# nrf52 register map
Vendor: Nordic Semiconductor; Series: nrf52; File version: 1
CPU: CM4 r0p1, little endian, MPU, FPU, 3 interrupt priority bits
Registers are 32-bit, read-write, reset 0x0 unless marked. A register's access mark holds for its fields unless they carry their own. Offsets are from the block's base; [hi:lo] are bit positions; 'fields as' and 'values as' point back to an identical list.

## CLOCK — Clock control
Base 0x40000000; alternate view of APPROTECT
0x00 TASKS_HFCLKSTART wo — Start HFCLK crystal oscillator
  [0] TASKS_HFCLKSTART
    1=Trigger task
0x04 TASKS_HFCLKSTOP wo — Stop HFCLK crystal oscillator
  [0] TASKS_HFCLKSTOP
    1=Trigger task
0x08 TASKS_LFCLKSTART wo — Start LFCLK source
  [0] TASKS_LFCLKSTART
    1=Trigger task
0x0C TASKS_LFCLKSTOP wo — Stop LFCLK source
  [0] TASKS_LFCLKSTOP
    1=Trigger task
0x10 TASKS_CAL wo — Start calibration of LFRC oscillator
  [0] TASKS_CAL
    1=Trigger task
0x14 TASKS_CTSTART wo — Start calibration timer
  [0] TASKS_CTSTART
    1=Trigger task
0x18 TASKS_CTSTOP wo — Stop calibration timer
  [0] TASKS_CTSTOP
    1=Trigger task
0x100 EVENTS_HFCLKSTARTED — HFCLK oscillator started
  [0] EVENTS_HFCLKSTARTED
    0=NotGenerated (Event not generated); 1=Generated (Event generated)
0x104 EVENTS_LFCLKSTARTED — LFCLK started
  [0] EVENTS_LFCLKSTARTED
    values as EVENTS_HFCLKSTARTED.EVENTS_HFCLKSTARTED
0x10C EVENTS_DONE — Calibration of LFCLK RC oscillator complete event
  [0] EVENTS_DONE
    values as EVENTS_HFCLKSTARTED.EVENTS_HFCLKSTARTED
0x110 EVENTS_CTTO — Calibration timer timeout
  [0] EVENTS_CTTO
    values as EVENTS_HFCLKSTARTED.EVENTS_HFCLKSTARTED
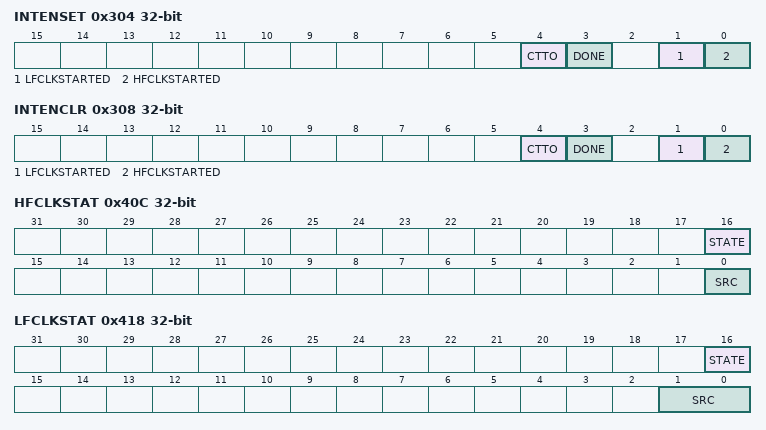
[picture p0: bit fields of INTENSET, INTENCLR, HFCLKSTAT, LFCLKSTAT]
0x304 INTENSET — Enable interrupt
  [all] fields
    on read: 0=Disabled (Read: Disabled); 1=Enabled (Read: Enabled) | on write: 1=Set (Enable)
  [4] CTTO — Write '1' to enable interrupt for event CTTO
  [3] DONE — Write '1' to enable interrupt for event DONE
  [1] LFCLKSTARTED — Write '1' to enable interrupt for event LFCLKSTARTED
  [0] HFCLKSTARTED — Write '1' to enable interrupt for event HFCLKSTARTED
0x308 INTENCLR — Disable interrupt
  [all] fields
    on read: 0=Disabled (Read: Disabled); 1=Enabled (Read: Enabled) | on write: 1=Clear (Disable)
  [4] CTTO — Write '1' to disable interrupt for event CTTO
  [3] DONE — Write '1' to disable interrupt for event DONE
  [1] LFCLKSTARTED — Write '1' to disable interrupt for event LFCLKSTARTED
  [0] HFCLKSTARTED — Write '1' to disable interrupt for event HFCLKSTARTED
0x408 HFCLKRUN ro — Status indicating that HFCLKSTART task has been triggered
  [0] STATUS — HFCLKSTART task triggered or not
    0=NotTriggered (Task not triggered); 1=Triggered (Task triggered)
0x40C HFCLKSTAT ro — HFCLK status
  [16] STATE — HFCLK state
    0=NotRunning (HFCLK not running); 1=Running (HFCLK running)
  [0] SRC — Source of HFCLK
    0=RC (64 MHz internal oscillator (HFINT)); 1=Xtal (64 MHz crystal oscillator (HFXO))
0x414 LFCLKRUN ro — Status indicating that LFCLKSTART task has been triggered
  [0] STATUS — LFCLKSTART task triggered or not
    values as HFCLKRUN.STATUS
0x418 LFCLKSTAT ro — LFCLK status
  [16] STATE — LFCLK state
    0=NotRunning (LFCLK not running); 1=Running (LFCLK running)
  [1:0] SRC — Source of LFCLK
    0=RC (32.768 kHz RC oscillator); 1=Xtal (32.768 kHz crystal oscillator); 2=Synth (32.768 kHz synthesized from HFCLK)
0x41C LFCLKSRCCOPY ro — Copy of LFCLKSRC register, set when LFCLKSTART task was triggered
  [1:0] SRC — Clock source
    values as LFCLKSTAT.SRC
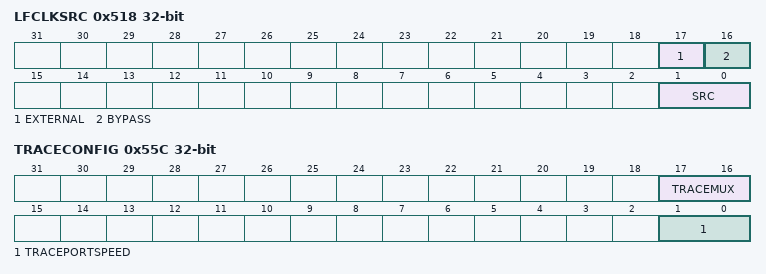
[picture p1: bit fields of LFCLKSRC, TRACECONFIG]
0x518 LFCLKSRC — Clock source for the LFCLK
  [17] EXTERNAL — Enable or disable external source for LFCLK
    0=Disabled (Disable external source (use with Xtal)); 1=Enabled (Enable use of external source instead of Xtal (SRC needs to be set to Xtal))
  [16] BYPASS — Enable or disable bypass of LFCLK crystal oscillator with external clock source
    0=Disabled (Disable (use with Xtal or low-swing external source)); 1=Enabled (Enable (use with rail-to-rail external source))
  [1:0] SRC — Clock source
    values as LFCLKSTAT.SRC
0x538 CTIV — Calibration timer interval
  [6:0] CTIV — Calibration timer interval in multiple of 0.25 seconds. Range: 0.25 seconds to 31.75 seconds.
0x55C TRACECONFIG — Clocking options for the Trace Port debug interface
  [17:16] TRACEMUX — Pin multiplexing of trace signals.
    0=GPIO (GPIOs multiplexed onto all trace-pins); 1=Serial (SWO multiplexed onto P0.18, GPIO multiplexed onto other trace pins); 2=Parallel (TRACECLK and TRACEDATA multiplexed onto P0.20, P0.18, P0.16, P0.15 and P0.14.)
  [1:0] TRACEPORTSPEED — Speed of Trace Port clock. Note that the TRACECLK pin will output this clock divided by two.
    0=32 MHz Trace Port clock (TRACECLK = 16 MHz); 1=16 MHz Trace Port clock (TRACECLK = 8 MHz); 2=8 MHz Trace Port clock (TRACECLK = 4 MHz); 3=4 MHz Trace Port clock (TRACECLK = 2 MHz)

## Notices in the file
Copyright (c) 2010 - 2024, Nordic Semiconductor ASA All rights reserved.
SPDX-License-Identifier: BSD-3-Clause
Redistribution and use in source and binary forms, with or without
modification, are permitted provided that the following conditions are met:
1. Redistributions of source code must retain the above copyright notice, this
list of conditions and the following disclaimer.
2. Redistributions in binary form must reproduce the above copyright
notice, this list of conditions and the following disclaimer in the
documentation and/or other materials provided with the distribution.
3. Neither the name of Nordic Semiconductor ASA nor the names of its
contributors may be used to endorse or promote products derived from this
software without specific prior written permission.
THIS SOFTWARE IS PROVIDED BY THE COPYRIGHT HOLDERS AND CONTRIBUTORS "AS IS"
AND ANY EXPRESS OR IMPLIED WARRANTIES, INCLUDING, BUT NOT LIMITED TO, THE
IMPLIED WARRANTIES OF MERCHANTABILITY, AND FITNESS FOR A PARTICULAR PURPOSE
ARE DISCLAIMED. IN NO EVENT SHALL NORDIC SEMICONDUCTOR ASA OR CONTRIBUTORS BE
LIABLE FOR ANY DIRECT, INDIRECT, INCIDENTAL, SPECIAL, EXEMPLARY, OR
CONSEQUENTIAL DAMAGES (INCLUDING, BUT NOT LIMITED TO, PROCUREMENT OF
SUBSTITUTE GOODS OR SERVICES; LOSS OF USE, DATA, OR PROFITS; OR BUSINESS
INTERRUPTION) HOWEVER CAUSED AND ON ANY THEORY OF LIABILITY, WHETHER IN
CONTRACT, STRICT LIABILITY, OR TORT (INCLUDING NEGLIGENCE OR OTHERWISE)
ARISING IN ANY WAY OUT OF THE USE OF THIS SOFTWARE, EVEN IF ADVISED OF THE
POSSIBILITY OF SUCH DAMAGE.
